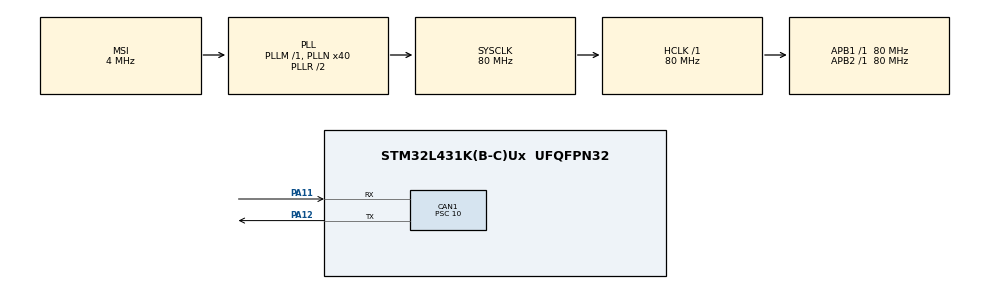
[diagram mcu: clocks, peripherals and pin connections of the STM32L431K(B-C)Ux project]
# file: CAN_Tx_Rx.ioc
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CAN1.BS1=CAN_BS1_5TQ
CAN1.BS2=CAN_BS2_2TQ
CAN1.CalculateBaudRate=1000000
CAN1.CalculateTimeBit=1000
CAN1.CalculateTimeQuantum=125.0
CAN1.Prescaler=10
Mcu.Family=STM32L4
Mcu.Name=STM32L431K(B-C)Ux
Mcu.Package=UFQFPN32
NVIC.PriorityGroup=NVIC_PRIORITYGROUP_4
PA11.Mode=CAN_Activate
PA11.Signal=CAN1_RX
PA12.Mode=CAN_Activate
PA12.Signal=CAN1_TX
PA13\ (JTMS-SWDIO).Mode=Trace_Asynchronous_SW
PA13\ (JTMS-SWDIO).Signal=SYS_JTMS-SWDIO
PA14\ (JTCK-SWCLK).Mode=Trace_Asynchronous_SW
PA14\ (JTCK-SWCLK).Signal=SYS_JTCK-SWCLK
PB3\ (JTDO-TRACESWO).Mode=Trace_Asynchronous_SW
PB3\ (JTDO-TRACESWO).Signal=SYS_JTDO-SWO
ProjectManager.HeapSize=0x200
ProjectManager.StackSize=0x400
ProjectManager.TargetToolchain=STM32CubeIDE
RCC.AHBFreq_Value=80000000
RCC.APB1Freq_Value=80000000
RCC.APB1TimFreq_Value=80000000
RCC.APB2Freq_Value=80000000
RCC.APB2TimFreq_Value=80000000
RCC.CortexFreq_Value=80000000
RCC.HCLKFreq_Value=80000000
RCC.HSE_VALUE=8000000
RCC.HSI48_VALUE=48000000
RCC.HSI_VALUE=16000000
RCC.LSE_VALUE=32768
RCC.MSI_VALUE=4000000
RCC.PLLN=40
RCC.SYSCLKFreq_VALUE=80000000
RCC.SYSCLKSource=RCC_SYSCLKSOURCE_PLLCLK
RCC.VCOOutputFreq_Value=160000000
board=custom

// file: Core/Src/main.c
/* USER CODE BEGIN Header */
/**
  ******************************************************************************
  * @file           : main.c
  * @brief          : Main program body
  ******************************************************************************
  * @attention
  *
  * Copyright (c) 2025 STMicroelectronics.
  * All rights reserved.
  *
  * This software is licensed under terms that can be found in the LICENSE file
  * in the root directory of this software component.
  * If no LICENSE file comes with this software, it is provided AS-IS.
  *
  ******************************************************************************
  */
/* USER CODE END Header */
#include "main.h"

/* USER CODE BEGIN Includes */
#include <stdio.h>
/* USER CODE END Includes */

CAN_HandleTypeDef hcan1;

void SystemClock_Config(void);
static void MX_GPIO_Init(void);
static void MX_CAN1_Init(void);

/* USER CODE BEGIN 0 */
CAN_RxHeaderTypeDef rxHeader = {0};
uint8_t rxFIFO[8] = {0};
uint8_t rxMsg1[8] = {0};
uint8_t rxMsg2[8] = {0};
/* USER CODE END 0 */

int main(void)
{

  /* USER CODE BEGIN 1 */
  HAL_StatusTypeDef res = HAL_OK;
  uint8_t msg1Check[] = {0x01, 0x01, 0x01};
  /* USER CODE END 1 */

  /* MCU Configuration--------------------------------------------------------*/

  /* Reset of all peripherals, Initializes the Flash interface and the Systick. */
  HAL_Init();

  /* Configure the system clock */
  SystemClock_Config();

  /* Initialize all configured peripherals */
  MX_GPIO_Init();
  MX_CAN1_Init();
  /* USER CODE BEGIN 2 */
  CAN_FilterTypeDef canfil;
  canfil.FilterBank = 0;
  canfil.FilterMode = CAN_FILTERMODE_IDMASK;
  canfil.FilterFIFOAssignment = CAN_RX_FIFO0;
  canfil.FilterIdHigh = 0;
  canfil.FilterIdLow = 0;
  canfil.FilterMaskIdHigh = 0;
  canfil.FilterMaskIdLow = 0;
  canfil.FilterScale = CAN_FILTERSCALE_32BIT;
  canfil.FilterActivation = CAN_FILTER_ENABLE;
  canfil.SlaveStartFilterBank = 0;
  res = HAL_CAN_ConfigFilter(&hcan1, &canfil);

  res = HAL_CAN_Start(&hcan1);

  CAN_TxHeaderTypeDef txHeader;
  txHeader.ExtId = 0x1000201;
  txHeader.IDE = CAN_ID_EXT;
  txHeader.RTR = CAN_RTR_DATA;
  txHeader.DLC = 3;
  txHeader.TransmitGlobalTime = DISABLE;

  uint8_t txMsg2[] = {0x01, 0x0F, 0xFF};

  uint32_t txMailbox;
  /* USER CODE END 2 */

  /* Infinite loop */
  /* USER CODE BEGIN WHILE */
  while (1)
  {
    // Rx msg1
    while(!(HAL_CAN_GetRxFifoFillLevel(&hcan1, CAN_RX_FIFO0) > 0)) {} //wait for message
    res = HAL_CAN_GetRxMessage(&hcan1, CAN_RX_FIFO0, &rxHeader, rxMsg1);

    // Clear Rx FIFO
    while(HAL_CAN_GetRxFifoFillLevel(&hcan1, CAN_RX_FIFO0) > 0) {
      HAL_CAN_GetRxMessage(&hcan1, CAN_RX_FIFO0, &rxHeader, rxFIFO);
    }

    // Tx msg2
    res = HAL_CAN_AddTxMessage(&hcan1, &txHeader, txMsg2, &txMailbox);
    HAL_Delay(10);

    // Rx msg2
    while(!(HAL_CAN_GetRxFifoFillLevel(&hcan1, CAN_RX_FIFO0) > 0)) {}
    res = HAL_CAN_GetRxMessage(&hcan1, CAN_RX_FIFO0, &rxHeader, rxMsg2);

    // Check messages
    if (rxMsg1[0] != msg1Check[0]
      || rxMsg1[1] != msg1Check[1]
      || rxMsg1[2] != msg1Check[2]) {
      printf("Rx NOT working, debug periph. to test Tx \n");
    } else if (rxMsg2[0] != txMsg2[0]
            || rxMsg2[1] != txMsg2[1]
            || rxMsg2[2] != txMsg2[2]) {
      printf("Rx working, Tx NOT working");
    } else {
      printf("Rx and Tx working");
    }
    /* USER CODE END WHILE */

  }
}

void SystemClock_Config(void)
{
  RCC_OscInitTypeDef RCC_OscInitStruct = {0};
  RCC_ClkInitTypeDef RCC_ClkInitStruct = {0};

  /** Configure the main internal regulator output voltage
  */
  if (HAL_PWREx_ControlVoltageScaling(PWR_REGULATOR_VOLTAGE_SCALE1) != HAL_OK)
  {
    Error_Handler();
  }

  /** Initializes the RCC Oscillators according to the specified parameters
  * in the RCC_OscInitTypeDef structure.
  */
  RCC_OscInitStruct.OscillatorType = RCC_OSCILLATORTYPE_MSI;
  RCC_OscInitStruct.MSIState = RCC_MSI_ON;
  RCC_OscInitStruct.MSICalibrationValue = 0;
  RCC_OscInitStruct.MSIClockRange = RCC_MSIRANGE_6;
  RCC_OscInitStruct.PLL.PLLState = RCC_PLL_ON;
  RCC_OscInitStruct.PLL.PLLSource = RCC_PLLSOURCE_MSI;
  RCC_OscInitStruct.PLL.PLLM = 1;
  RCC_OscInitStruct.PLL.PLLN = 40;
  RCC_OscInitStruct.PLL.PLLP = RCC_PLLP_DIV7;
  RCC_OscInitStruct.PLL.PLLQ = RCC_PLLQ_DIV2;
  RCC_OscInitStruct.PLL.PLLR = RCC_PLLR_DIV2;
  if (HAL_RCC_OscConfig(&RCC_OscInitStruct) != HAL_OK)
  {
    Error_Handler();
  }

  /** Initializes the CPU, AHB and APB buses clocks
  */
  RCC_ClkInitStruct.ClockType = RCC_CLOCKTYPE_HCLK|RCC_CLOCKTYPE_SYSCLK
                              |RCC_CLOCKTYPE_PCLK1|RCC_CLOCKTYPE_PCLK2;
  RCC_ClkInitStruct.SYSCLKSource = RCC_SYSCLKSOURCE_PLLCLK;
  RCC_ClkInitStruct.AHBCLKDivider = RCC_SYSCLK_DIV1;
  RCC_ClkInitStruct.APB1CLKDivider = RCC_HCLK_DIV1;
  RCC_ClkInitStruct.APB2CLKDivider = RCC_HCLK_DIV1;

  if (HAL_RCC_ClockConfig(&RCC_ClkInitStruct, FLASH_LATENCY_4) != HAL_OK)
  {
    Error_Handler();
  }
}

static void MX_CAN1_Init(void)
{

  hcan1.Instance = CAN1;
  hcan1.Init.Prescaler = 10;
  hcan1.Init.Mode = CAN_MODE_NORMAL;
  hcan1.Init.SyncJumpWidth = CAN_SJW_1TQ;
  hcan1.Init.TimeSeg1 = CAN_BS1_5TQ;
  hcan1.Init.TimeSeg2 = CAN_BS2_2TQ;
  hcan1.Init.TimeTriggeredMode = DISABLE;
  hcan1.Init.AutoBusOff = DISABLE;
  hcan1.Init.AutoWakeUp = DISABLE;
  hcan1.Init.AutoRetransmission = DISABLE;
  hcan1.Init.ReceiveFifoLocked = DISABLE;
  hcan1.Init.TransmitFifoPriority = DISABLE;
  if (HAL_CAN_Init(&hcan1) != HAL_OK)
  {
    Error_Handler();
  }

}

static void MX_GPIO_Init(void)
{

  /* GPIO Ports Clock Enable */
  __HAL_RCC_GPIOA_CLK_ENABLE();
  __HAL_RCC_GPIOB_CLK_ENABLE();

}

/* USER CODE BEGIN 4 */
int __io_putchar(int ch)
{
  return ITM_SendChar(ch);
}
/* USER CODE END 4 */

void Error_Handler(void)
{
  __disable_irq();
  while (1)
  {
  }
}
